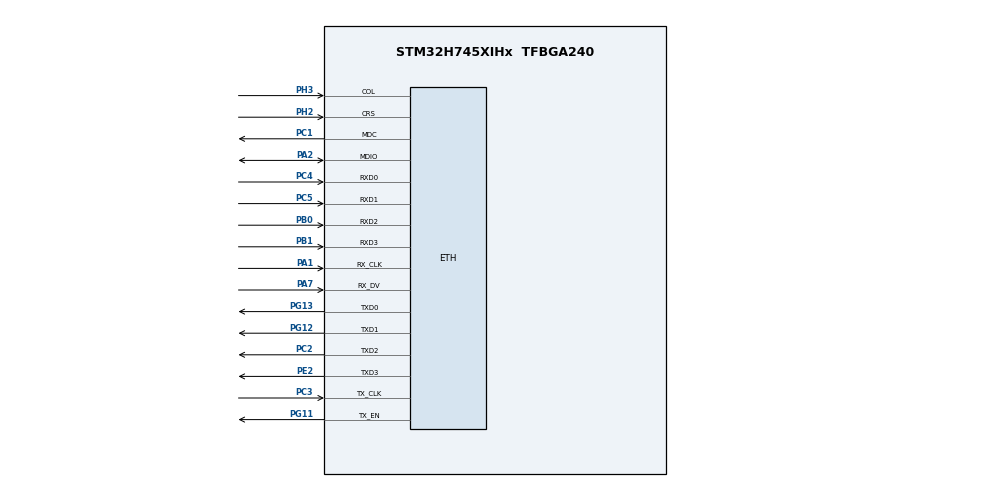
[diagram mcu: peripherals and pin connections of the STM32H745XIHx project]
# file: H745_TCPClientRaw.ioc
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CORTEX_M7.AccessPermission-Cortex_Memory_Protection_Unit_Region0_Settings=MPU_REGION_FULL_ACCESS
CORTEX_M7.BaseAddress-Cortex_Memory_Protection_Unit_Region0_Settings=0x30040000
CORTEX_M7.CPU_DCache=Enabled
CORTEX_M7.CPU_ICache=Enabled
CORTEX_M7.DisableExec-Cortex_Memory_Protection_Unit_Region0_Settings=MPU_INSTRUCTION_ACCESS_DISABLE
CORTEX_M7.Enable-Cortex_Memory_Protection_Unit_Region0_Settings=MPU_REGION_ENABLE
CORTEX_M7.IsShareable-Cortex_Memory_Protection_Unit_Region0_Settings=MPU_ACCESS_SHAREABLE
CORTEX_M7.MPU_Control=MPU_PRIVILEGED_DEFAULT
CORTEX_M7.Size-Cortex_Memory_Protection_Unit_Region0_Settings=MPU_REGION_SIZE_32KB
CORTEX_M7.TypeExtField-Cortex_Memory_Protection_Unit_Region0_Settings=MPU_TEX_LEVEL1
CortexM4.IPs=FATFS_M4\:I,FREERTOS_M4\:I,IWDG2\:I,RCC,USB_DEVICE_M4\:I,USB_HOST_M4\:I,WWDG2\:I,DMA,BDMA,MDMA,NVIC2\:I,SAI4\:I,DEBUG,PDM2PCM_M4\:I,PWR,RESMGR_UTILITY,SYS_M4\:I,CORTEX_M4\:I,OPENAMP_M4\:I,VREFBUF
CortexM7.IPs=FATFS_M7\:I,FREERTOS_M7\:I,IWDG1\:I,RCC\:I,USB_DEVICE_M7\:I,USB_HOST_M7\:I,WWDG1\:I,DMA\:I,BDMA\:I,MDMA\:I,NVIC1\:I,CORTEX_M7\:I,DEBUG\:I,PDM2PCM_M7\:I,PWR\:I,RESMGR_UTILITY\:I,SYS\:I,OPENAMP_M7\:I,VREFBUF\:I,ETH\:I,LWIP\:I,TIM1\:I
ETH.MediaInterface=HAL_ETH_MII_MODE
LWIP.BSP.number=1
LWIP.GATEWAY_ADDRESS=192.168.000.001
LWIP.IP_ADDRESS=192.168.000.010
LWIP.LWIP_DHCP=0
LWIP.MEM_SIZE=10*1024
LWIP.NETMASK_ADDRESS=255.255.255.000
LWIP.Version=v2.1.2_Cube
LWIP0.BSP.STBoard=false
LWIP0.BSP.api=BSP_COMPONENT_DRIVER
LWIP0.BSP.component=LAN8742
LWIP0.BSP.i2caddr=0
LWIP0.BSP.instance=LAN8742
LWIP0.BSP.name=Driver_PHY
LWIP0.BSP.solution=LAN8742
Mcu.Family=STM32H7
Mcu.Name=STM32H745XIHx
Mcu.Package=TFBGA240
NVIC1.ETH_IRQn=true\:0\:0\:false\:false\:true\:true\:true
NVIC1.PriorityGroup=NVIC_PRIORITYGROUP_4
NVIC1.TIM1_UP_IRQn=true\:0\:0\:false\:false\:true\:true\:true
NVIC2.PriorityGroup=NVIC_PRIORITYGROUP_4
PA1.Mode=MII
PA1.PinAttribute=CortexM7
PA1.Signal=ETH_RX_CLK
PA2.Mode=MII
PA2.PinAttribute=CortexM7
PA2.Signal=ETH_MDIO
PA7.Mode=MII
PA7.PinAttribute=CortexM7
PA7.Signal=ETH_RX_DV
PB0.Mode=MII
PB0.PinAttribute=CortexM7
PB0.Signal=ETH_RXD2
PB1.Mode=MII
PB1.PinAttribute=CortexM7
PB1.Signal=ETH_RXD3
PC1.Mode=MII
PC1.PinAttribute=CortexM7
PC1.Signal=ETH_MDC
PC2.Mode=MII
PC2.PinAttribute=CortexM7
PC2.Signal=ETH_TXD2
PC3.Mode=MII
PC3.PinAttribute=CortexM7
PC3.Signal=ETH_TX_CLK
PC4.Mode=MII
PC4.PinAttribute=CortexM7
PC4.Signal=ETH_RXD0
PC5.Mode=MII
PC5.PinAttribute=CortexM7
PC5.Signal=ETH_RXD1
PE2.Mode=MII
PE2.PinAttribute=CortexM7
PE2.Signal=ETH_TXD3
PG11.Mode=MII
PG11.PinAttribute=CortexM7
PG11.Signal=ETH_TX_EN
PG12.Mode=MII
PG12.PinAttribute=CortexM7
PG12.Signal=ETH_TXD1
PG13.Mode=MII
PG13.PinAttribute=CortexM7
PG13.Signal=ETH_TXD0
PH0-OSC_IN\ (PH0).Mode=HSE-External-Oscillator
PH0-OSC_IN\ (PH0).PinAttribute=CortexM7
PH0-OSC_IN\ (PH0).Signal=RCC_OSC_IN
PH1-OSC_OUT\ (PH1).Mode=HSE-External-Oscillator
PH1-OSC_OUT\ (PH1).PinAttribute=CortexM7
PH1-OSC_OUT\ (PH1).Signal=RCC_OSC_OUT
PH2.Mode=MII
PH2.PinAttribute=CortexM7
PH2.Signal=ETH_CRS
PH3.Mode=MII
PH3.PinAttribute=CortexM7
PH3.Signal=ETH_COL
PI10.PinAttribute=CortexM7
PI10.Signal=ETH_RX_ER
ProjectManager.HeapSize=M4-0x200,M7-0x200
ProjectManager.StackSize=M4-0x400,M7-0x400
ProjectManager.TargetToolchain=STM32CubeIDE
RCC.ADCFreq_Value=50390625
RCC.APB1Freq_Value=120000000
RCC.APB2Freq_Value=120000000
RCC.APB3Freq_Value=120000000
RCC.APB4Freq_Value=120000000
RCC.CortexFreq_Value=480000000
RCC.D1PPRE=RCC_APB3_DIV2
RCC.D2PPRE1=RCC_APB1_DIV2
RCC.D2PPRE2=RCC_APB2_DIV2
RCC.D3PPRE=RCC_APB4_DIV2
RCC.DIVM1=5
RCC.DIVN1=192
RCC.DIVQ1=4
RCC.DIVR1=4
RCC.HCLKFreq_Value=240000000
RCC.HPRE=RCC_HCLK_DIV2
RCC.PLL2FRACN=0
RCC.PLL3FRACN=0
RCC.PLLFRACN=0
RCC.PLLSourceVirtual=RCC_PLLSOURCE_HSE
RCC.PWR_Regulator_Voltage_Scale=PWR_REGULATOR_VOLTAGE_SCALE0
RCC.SYSCLKFreq_VALUE=480000000
RCC.SYSCLKSource=RCC_SYSCLKSOURCE_PLLCLK
RCC.SupplySource=PWR_DIRECT_SMPS_SUPPLY
RCC.USBFreq_Value=240000000
TIM1.Period=10000-1
TIM1.Prescaler=24000-1
TIM1.TIM_MasterOutputTrigger=TIM_TRGO_RESET
VP_LWIP_VS_Enabled.Mode=Enabled
VP_SYS_M4_VS_Systick.Mode=SysTick
VP_TIM1_VS_ClockSourceINT.Mode=Internal
board=STM32H745I-DISCO

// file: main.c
/* USER CODE BEGIN Header */
/**
  ******************************************************************************
  * @file           : main.c
  * @brief          : Main program body
  ******************************************************************************
  * @attention
  *
  * <h2><center>&copy; Copyright (c) 2021 STMicroelectronics.
  * All rights reserved.</center></h2>
  *
  * This software component is licensed by ST under BSD 3-Clause license,
  * the "License"; You may not use this file except in compliance with the
  * License. You may obtain a copy of the License at:
  *                        opensource.org/licenses/BSD-3-Clause
  *
  ******************************************************************************
  */
/* USER CODE END Header */
#include "main.h"
#include "lwip.h"

/* USER CODE BEGIN Includes */
#include "tcpClientRAW.h"
/* USER CODE END Includes */

/* USER CODE BEGIN PD */

#ifndef HSEM_ID_0
#define HSEM_ID_0 (0U) /* HW semaphore 0*/
#endif
/* USER CODE END PD */

TIM_HandleTypeDef htim1;

void SystemClock_Config(void);
static void MPU_Config(void);
static void MX_GPIO_Init(void);
static void MX_TIM1_Init(void);

/* USER CODE BEGIN 0 */

struct netif gnetif;
/* USER CODE END 0 */

int main(void)
{
/* USER CODE BEGIN Boot_Mode_Sequence_0 */
//  int32_t timeout;
/* USER CODE END Boot_Mode_Sequence_0 */

  /* MPU Configuration--------------------------------------------------------*/
  MPU_Config();

  /* Enable I-Cache---------------------------------------------------------*/
  SCB_EnableICache();

  /* Enable D-Cache---------------------------------------------------------*/
  SCB_EnableDCache();

/* USER CODE BEGIN Boot_Mode_Sequence_1 */
  /* Wait until CPU2 boots and enters in stop mode or timeout*/
//  timeout = 0xFFFF;
//  while((__HAL_RCC_GET_FLAG(RCC_FLAG_D2CKRDY) != RESET) && (timeout-- > 0));
//  if ( timeout < 0 )
//  {
//  Error_Handler();
//  }
/* USER CODE END Boot_Mode_Sequence_1 */
  /* MCU Configuration--------------------------------------------------------*/

  /* Reset of all peripherals, Initializes the Flash interface and the Systick. */
  HAL_Init();

  /* Configure the system clock */
  SystemClock_Config();
/* USER CODE BEGIN Boot_Mode_Sequence_2 */
/* When system initialization is finished, Cortex-M7 will release Cortex-M4 by means of
HSEM notification */
/*HW semaphore Clock enable*/
//__HAL_RCC_HSEM_CLK_ENABLE();
///*Take HSEM */
//HAL_HSEM_FastTake(HSEM_ID_0);
///*Release HSEM in order to notify the CPU2(CM4)*/
//HAL_HSEM_Release(HSEM_ID_0,0);
///* wait until CPU2 wakes up from stop mode */
//timeout = 0xFFFF;
//while((__HAL_RCC_GET_FLAG(RCC_FLAG_D2CKRDY) == RESET) && (timeout-- > 0));
//if ( timeout < 0 )
//{
//Error_Handler();
//}
/* USER CODE END Boot_Mode_Sequence_2 */

  /* Initialize all configured peripherals */
  MX_GPIO_Init();
  MX_LWIP_Init();
  MX_TIM1_Init();
  /* USER CODE BEGIN 2 */

  HAL_TIM_Base_Start_IT(&htim1);

  tcp_client_init();

  /* USER CODE END 2 */

  /* Infinite loop */
  while (1)
  {

    /* USER CODE BEGIN 3 */

	  ethernetif_input(&gnetif);
	  sys_check_timeouts();
  }
  /* USER CODE END 3 */
}

void SystemClock_Config(void)
{
  RCC_OscInitTypeDef RCC_OscInitStruct = {0};
  RCC_ClkInitTypeDef RCC_ClkInitStruct = {0};

  /** Supply configuration update enable
  */
  HAL_PWREx_ConfigSupply(PWR_DIRECT_SMPS_SUPPLY);
  /** Configure the main internal regulator output voltage
  */
  __HAL_PWR_VOLTAGESCALING_CONFIG(PWR_REGULATOR_VOLTAGE_SCALE0);

  while(!__HAL_PWR_GET_FLAG(PWR_FLAG_VOSRDY)) {}
  /** Initializes the RCC Oscillators according to the specified parameters
  * in the RCC_OscInitTypeDef structure.
  */
  RCC_OscInitStruct.OscillatorType = RCC_OSCILLATORTYPE_HSE;
  RCC_OscInitStruct.HSEState = RCC_HSE_ON;
  RCC_OscInitStruct.PLL.PLLState = RCC_PLL_ON;
  RCC_OscInitStruct.PLL.PLLSource = RCC_PLLSOURCE_HSE;
  RCC_OscInitStruct.PLL.PLLM = 5;
  RCC_OscInitStruct.PLL.PLLN = 192;
  RCC_OscInitStruct.PLL.PLLP = 2;
  RCC_OscInitStruct.PLL.PLLQ = 4;
  RCC_OscInitStruct.PLL.PLLR = 4;
  RCC_OscInitStruct.PLL.PLLRGE = RCC_PLL1VCIRANGE_2;
  RCC_OscInitStruct.PLL.PLLVCOSEL = RCC_PLL1VCOWIDE;
  RCC_OscInitStruct.PLL.PLLFRACN = 0;
  if (HAL_RCC_OscConfig(&RCC_OscInitStruct) != HAL_OK)
  {
    Error_Handler();
  }
  /** Initializes the CPU, AHB and APB buses clocks
  */
  RCC_ClkInitStruct.ClockType = RCC_CLOCKTYPE_HCLK|RCC_CLOCKTYPE_SYSCLK
                              |RCC_CLOCKTYPE_PCLK1|RCC_CLOCKTYPE_PCLK2
                              |RCC_CLOCKTYPE_D3PCLK1|RCC_CLOCKTYPE_D1PCLK1;
  RCC_ClkInitStruct.SYSCLKSource = RCC_SYSCLKSOURCE_PLLCLK;
  RCC_ClkInitStruct.SYSCLKDivider = RCC_SYSCLK_DIV1;
  RCC_ClkInitStruct.AHBCLKDivider = RCC_HCLK_DIV2;
  RCC_ClkInitStruct.APB3CLKDivider = RCC_APB3_DIV2;
  RCC_ClkInitStruct.APB1CLKDivider = RCC_APB1_DIV2;
  RCC_ClkInitStruct.APB2CLKDivider = RCC_APB2_DIV2;
  RCC_ClkInitStruct.APB4CLKDivider = RCC_APB4_DIV2;

  if (HAL_RCC_ClockConfig(&RCC_ClkInitStruct, FLASH_LATENCY_4) != HAL_OK)
  {
    Error_Handler();
  }
}

static void MX_TIM1_Init(void)
{

  TIM_ClockConfigTypeDef sClockSourceConfig = {0};
  TIM_MasterConfigTypeDef sMasterConfig = {0};

  htim1.Instance = TIM1;
  htim1.Init.Prescaler = 24000-1;
  htim1.Init.CounterMode = TIM_COUNTERMODE_UP;
  htim1.Init.Period = 10000-1;
  htim1.Init.ClockDivision = TIM_CLOCKDIVISION_DIV1;
  htim1.Init.RepetitionCounter = 0;
  htim1.Init.AutoReloadPreload = TIM_AUTORELOAD_PRELOAD_DISABLE;
  if (HAL_TIM_Base_Init(&htim1) != HAL_OK)
  {
    Error_Handler();
  }
  sClockSourceConfig.ClockSource = TIM_CLOCKSOURCE_INTERNAL;
  if (HAL_TIM_ConfigClockSource(&htim1, &sClockSourceConfig) != HAL_OK)
  {
    Error_Handler();
  }
  sMasterConfig.MasterOutputTrigger = TIM_TRGO_RESET;
  sMasterConfig.MasterOutputTrigger2 = TIM_TRGO2_RESET;
  sMasterConfig.MasterSlaveMode = TIM_MASTERSLAVEMODE_DISABLE;
  if (HAL_TIMEx_MasterConfigSynchronization(&htim1, &sMasterConfig) != HAL_OK)
  {
    Error_Handler();
  }

}

static void MX_GPIO_Init(void)
{

  /* GPIO Ports Clock Enable */
  __HAL_RCC_GPIOG_CLK_ENABLE();
  __HAL_RCC_GPIOE_CLK_ENABLE();
  __HAL_RCC_GPIOI_CLK_ENABLE();
  __HAL_RCC_GPIOH_CLK_ENABLE();
  __HAL_RCC_GPIOC_CLK_ENABLE();
  __HAL_RCC_GPIOA_CLK_ENABLE();
  __HAL_RCC_GPIOB_CLK_ENABLE();

}

/* MPU Configuration */

void MPU_Config(void)
{
  MPU_Region_InitTypeDef MPU_InitStruct = {0};

  /* Disables the MPU */
  HAL_MPU_Disable();
  /** Initializes and configures the Region and the memory to be protected
  */
  MPU_InitStruct.Enable = MPU_REGION_ENABLE;
  MPU_InitStruct.Number = MPU_REGION_NUMBER0;
  MPU_InitStruct.BaseAddress = 0x30040000;
  MPU_InitStruct.Size = MPU_REGION_SIZE_32KB;
  MPU_InitStruct.SubRegionDisable = 0x0;
  MPU_InitStruct.TypeExtField = MPU_TEX_LEVEL1;
  MPU_InitStruct.AccessPermission = MPU_REGION_FULL_ACCESS;
  MPU_InitStruct.DisableExec = MPU_INSTRUCTION_ACCESS_DISABLE;
  MPU_InitStruct.IsShareable = MPU_ACCESS_SHAREABLE;
  MPU_InitStruct.IsCacheable = MPU_ACCESS_NOT_CACHEABLE;
  MPU_InitStruct.IsBufferable = MPU_ACCESS_NOT_BUFFERABLE;

  HAL_MPU_ConfigRegion(&MPU_InitStruct);
  /* Enables the MPU */
  HAL_MPU_Enable(MPU_PRIVILEGED_DEFAULT);

}

void Error_Handler(void)
{
  __disable_irq();
  while (1)
  {
  }
}

/************************ (C) COPYRIGHT STMicroelectronics *****END OF FILE****/
